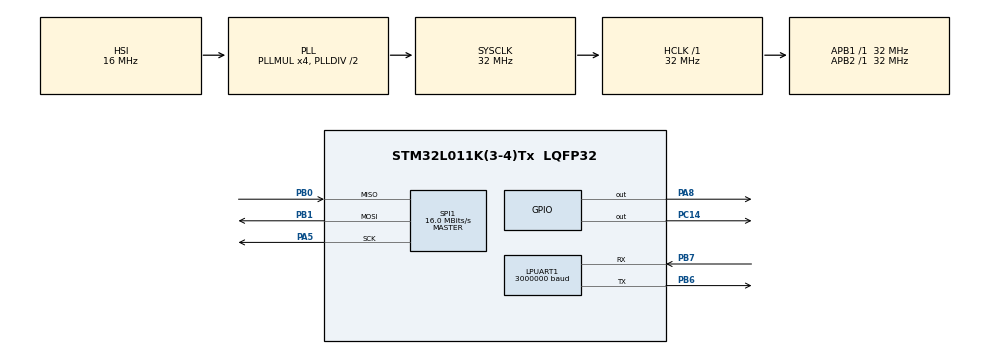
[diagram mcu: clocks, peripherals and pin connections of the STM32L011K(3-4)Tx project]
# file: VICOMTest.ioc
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LPUART1.BaudRate=3000000
LPUART1.Parity=UART_PARITY_NONE
LPUART1.WordLength=UART_WORDLENGTH_9B
Mcu.Family=STM32L0
Mcu.Name=STM32L011K(3-4)Tx
Mcu.Package=LQFP32
NVIC.LPUART1_IRQn=true\:0\:0\:false\:false\:true\:true\:true\:true
PA13.Mode=Serial_Wire
PA13.Signal=SYS_SWDIO
PA14.Mode=Serial_Wire
PA14.Signal=SYS_SWCLK
PA5.Mode=Full_Duplex_Master
PA5.Signal=SPI1_SCK
PA8.Signal=GPIO_Output
PB0.Mode=Full_Duplex_Master
PB0.Signal=SPI1_MISO
PB1.Mode=Full_Duplex_Master
PB1.Signal=SPI1_MOSI
PB6.Mode=Asynchronous
PB6.Signal=LPUART1_TX
PB7.Mode=Asynchronous
PB7.Signal=LPUART1_RX
PC14-OSC32_IN.Signal=GPIO_Output
ProjectManager.HeapSize=0x200
ProjectManager.StackSize=0x400
ProjectManager.TargetToolchain=Makefile
RCC.AHBFreq_Value=32000000
RCC.APB1Freq_Value=32000000
RCC.APB1TimFreq_Value=32000000
RCC.APB2Freq_Value=32000000
RCC.APB2TimFreq_Value=32000000
RCC.HCLKFreq_Value=32000000
RCC.HSE_VALUE=8000000
RCC.HSI16_VALUE=16000000
RCC.HSI_VALUE=16000000
RCC.LSE_VALUE=32768
RCC.MSI_VALUE=2097000
RCC.PLLMUL=RCC_PLLMUL_4
RCC.SYSCLKFreq_VALUE=32000000
RCC.SYSCLKSource=RCC_SYSCLKSOURCE_PLLCLK
RCC.VCOOutputFreq_Value=64000000
SPI1.CalculateBaudRate=16.0 MBits/s
SPI1.Direction=SPI_DIRECTION_2LINES
SPI1.Mode=SPI_MODE_MASTER
SPI1.VirtualType=VM_MASTER
VP_CRC_VS_CRC.Mode=CRC_Activate
board=custom

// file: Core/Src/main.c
/* USER CODE BEGIN Header */
/**
  ******************************************************************************
  * @file           : main.c
  * @brief          : Main program body
  ******************************************************************************
  * @attention
  *
  * Copyright (c) 2022 STMicroelectronics.
  * All rights reserved.
  *
  * This software is licensed under terms that can be found in the LICENSE file
  * in the root directory of this software component.
  * If no LICENSE file comes with this software, it is provided AS-IS.
  *
  ******************************************************************************
  */
/* USER CODE END Header */
#include "main.h"

CRC_HandleTypeDef hcrc;

UART_HandleTypeDef hlpuart1;

SPI_HandleTypeDef hspi1;

void SystemClock_Config(void);
static void MX_GPIO_Init(void);
static void MX_CRC_Init(void);
static void MX_LPUART1_UART_Init(void);
static void MX_SPI1_Init(void);

/* USER CODE BEGIN 0 */
uint8_t addr_buffer[1];
uint8_t size_buffer[1];
uint8_t data_buffer[1];
uint8_t addressCorrect = 0;
uint8_t sizeReceived = 0;

/* USER CODE END 0 */

int main(void)
{

  /* MCU Configuration--------------------------------------------------------*/

  /* Reset of all peripherals, Initializes the Flash interface and the Systick. */
  HAL_Init();

  /* Configure the system clock */
  SystemClock_Config();

  /* Initialize all configured peripherals */
  MX_GPIO_Init();
  MX_CRC_Init();
  MX_LPUART1_UART_Init();
  MX_SPI1_Init();
  /* USER CODE BEGIN 2 */
  char* Message = "Starting to receive data";
  HAL_UART_Transmit(&hlpuart1, (uint8_t *)Message, strlen(Message), 10);
  HAL_UART_Receive_IT(&hlpuart1, addr_buffer, 1);

  /* USER CODE END 2 */

  /* Infinite loop */
  while (1)
  {

    /* USER CODE BEGIN 3 */
    // uint8_t x = 65;
    // HAL_UART_Transmit(&hlpuart1, &x, 1, HAL_MAX_DELAY);
    // uint8_t rx_data[10];
    // HAL_UART_Receive(&hlpuart1, rx_data, 10 * sizeof(uint8_t));

    //want to implement uart handler. send your stm32 a message and get into that. i.e. from serial to usb to stm32 and be able to get into that.
    //whatt interupt to enable and how to do so. From there how to handle it.
    //next step would be clearing that interrupt so you get out of that.

    //address, length, payload.
    //1 byte, 1 byte, 256 bytes
  }
  /* USER CODE END 3 */
}

void SystemClock_Config(void)
{
  RCC_OscInitTypeDef RCC_OscInitStruct = {0};
  RCC_ClkInitTypeDef RCC_ClkInitStruct = {0};
  RCC_PeriphCLKInitTypeDef PeriphClkInit = {0};

  /** Configure the main internal regulator output voltage
  */
  __HAL_PWR_VOLTAGESCALING_CONFIG(PWR_REGULATOR_VOLTAGE_SCALE1);

  /** Initializes the RCC Oscillators according to the specified parameters
  * in the RCC_OscInitTypeDef structure.
  */
  RCC_OscInitStruct.OscillatorType = RCC_OSCILLATORTYPE_HSI;
  RCC_OscInitStruct.HSIState = RCC_HSI_ON;
  RCC_OscInitStruct.HSICalibrationValue = RCC_HSICALIBRATION_DEFAULT;
  RCC_OscInitStruct.PLL.PLLState = RCC_PLL_ON;
  RCC_OscInitStruct.PLL.PLLSource = RCC_PLLSOURCE_HSI;
  RCC_OscInitStruct.PLL.PLLMUL = RCC_PLLMUL_4;
  RCC_OscInitStruct.PLL.PLLDIV = RCC_PLLDIV_2;
  if (HAL_RCC_OscConfig(&RCC_OscInitStruct) != HAL_OK)
  {
    Error_Handler();
  }

  /** Initializes the CPU, AHB and APB buses clocks
  */
  RCC_ClkInitStruct.ClockType = RCC_CLOCKTYPE_HCLK|RCC_CLOCKTYPE_SYSCLK
                              |RCC_CLOCKTYPE_PCLK1|RCC_CLOCKTYPE_PCLK2;
  RCC_ClkInitStruct.SYSCLKSource = RCC_SYSCLKSOURCE_PLLCLK;
  RCC_ClkInitStruct.AHBCLKDivider = RCC_SYSCLK_DIV1;
  RCC_ClkInitStruct.APB1CLKDivider = RCC_HCLK_DIV1;
  RCC_ClkInitStruct.APB2CLKDivider = RCC_HCLK_DIV1;

  if (HAL_RCC_ClockConfig(&RCC_ClkInitStruct, FLASH_LATENCY_1) != HAL_OK)
  {
    Error_Handler();
  }
  PeriphClkInit.PeriphClockSelection = RCC_PERIPHCLK_LPUART1;
  PeriphClkInit.Lpuart1ClockSelection = RCC_LPUART1CLKSOURCE_PCLK1;
  if (HAL_RCCEx_PeriphCLKConfig(&PeriphClkInit) != HAL_OK)
  {
    Error_Handler();
  }
}

static void MX_CRC_Init(void)
{

  hcrc.Instance = CRC;
  hcrc.Init.DefaultPolynomialUse = DEFAULT_POLYNOMIAL_ENABLE;
  hcrc.Init.DefaultInitValueUse = DEFAULT_INIT_VALUE_ENABLE;
  hcrc.Init.InputDataInversionMode = CRC_INPUTDATA_INVERSION_NONE;
  hcrc.Init.OutputDataInversionMode = CRC_OUTPUTDATA_INVERSION_DISABLE;
  hcrc.InputDataFormat = CRC_INPUTDATA_FORMAT_BYTES;
  if (HAL_CRC_Init(&hcrc) != HAL_OK)
  {
    Error_Handler();
  }

}

static void MX_LPUART1_UART_Init(void)
{

  hlpuart1.Instance = LPUART1;
  hlpuart1.Init.BaudRate = 3000000;
  hlpuart1.Init.WordLength = UART_WORDLENGTH_9B;
  hlpuart1.Init.StopBits = UART_STOPBITS_1;
  hlpuart1.Init.Parity = UART_PARITY_NONE;
  hlpuart1.Init.Mode = UART_MODE_TX_RX;
  hlpuart1.Init.HwFlowCtl = UART_HWCONTROL_NONE;
  hlpuart1.Init.OneBitSampling = UART_ONE_BIT_SAMPLE_DISABLE;
  hlpuart1.AdvancedInit.AdvFeatureInit = UART_ADVFEATURE_NO_INIT;
  if (HAL_UART_Init(&hlpuart1) != HAL_OK)
  {
    Error_Handler();
  }

}

static void MX_SPI1_Init(void)
{

  /* SPI1 parameter configuration*/
  hspi1.Instance = SPI1;
  hspi1.Init.Mode = SPI_MODE_MASTER;
  hspi1.Init.Direction = SPI_DIRECTION_2LINES;
  hspi1.Init.DataSize = SPI_DATASIZE_8BIT;
  hspi1.Init.CLKPolarity = SPI_POLARITY_LOW;
  hspi1.Init.CLKPhase = SPI_PHASE_1EDGE;
  hspi1.Init.NSS = SPI_NSS_SOFT;
  hspi1.Init.BaudRatePrescaler = SPI_BAUDRATEPRESCALER_2;
  hspi1.Init.FirstBit = SPI_FIRSTBIT_MSB;
  hspi1.Init.TIMode = SPI_TIMODE_DISABLE;
  hspi1.Init.CRCCalculation = SPI_CRCCALCULATION_DISABLE;
  hspi1.Init.CRCPolynomial = 7;
  if (HAL_SPI_Init(&hspi1) != HAL_OK)
  {
    Error_Handler();
  }

}

static void MX_GPIO_Init(void)
{
  GPIO_InitTypeDef GPIO_InitStruct = {0};

  /* GPIO Ports Clock Enable */
  __HAL_RCC_GPIOC_CLK_ENABLE();
  __HAL_RCC_GPIOA_CLK_ENABLE();
  __HAL_RCC_GPIOB_CLK_ENABLE();

  /*Configure GPIO pin Output Level */
  HAL_GPIO_WritePin(GPIOC, GPIO_PIN_14, GPIO_PIN_RESET);

  /*Configure GPIO pin Output Level */
  HAL_GPIO_WritePin(GPIOA, GPIO_PIN_8, GPIO_PIN_RESET);

  /*Configure GPIO pin : PC14 */
  GPIO_InitStruct.Pin = GPIO_PIN_14;
  GPIO_InitStruct.Mode = GPIO_MODE_OUTPUT_PP;
  GPIO_InitStruct.Pull = GPIO_NOPULL;
  GPIO_InitStruct.Speed = GPIO_SPEED_FREQ_LOW;
  HAL_GPIO_Init(GPIOC, &GPIO_InitStruct);

  /*Configure GPIO pin : PA8 */
  GPIO_InitStruct.Pin = GPIO_PIN_8;
  GPIO_InitStruct.Mode = GPIO_MODE_OUTPUT_PP;
  GPIO_InitStruct.Pull = GPIO_NOPULL;
  GPIO_InitStruct.Speed = GPIO_SPEED_FREQ_LOW;
  HAL_GPIO_Init(GPIOA, &GPIO_InitStruct);

}

void Error_Handler(void)
{
  __disable_irq();
  while (1)
  {
  }
}
